# M051DN_v1 register map
File version: 1.0
Registers are 32-bit, read-write, reset 0x0 unless marked. A register's access mark holds for its fields unless they carry their own. Offsets are from the block's base; [hi:lo] are bit positions; {n}, {i} and the like mark numbered series; 'fields as' and 'values as' point back to an identical list.

## GP — GPIO Register Map
Base 0x50004000
{0x0+0x40*i} P{i}_PMD (reset mask 0xFFFF0000) (i=0..4) — P{i} I/O Mode Control
  [15:0] PMDn — Port 0-4 I/O Pin [N] Mode Control. Determine each I/O mode of Px.n pins. Note2: The default value is 0x0000_FFFF and all pins will be quasi-bidirectional mode after chip is powered on (only for M05xxBN). Note3: The initial value of this field is defined by CIOINI (CONFIG[10]) (only for M05xxDN/DE).If CIOINI is set to 1, the default value is 0x0000_FFFF and all pins will be quasi-bidirectional mode after chip powered on.If CIOINI is set to 0, the default value is 0x0000_0000 and all pins will be input tri-state mode after chip powered on.
    0=Px.n is in Input mode; 1=Px.n is in Push-pull Output mode; 2=Px.n is in Open-drain Output mode; 3=Px.n is in Quasi-bidirectional mode
{0x4+0x40*i} P{i}_OFFD (i=0..4) — P{i} Digital Input Path Disable Control
  [23:16] OFFD — Port 0-4 Pin [N] Digital Input Path Disable Control. Each of these bits is used to control if the digital input path of corresponding Px.n pin is disabled. If input is analog signal, users can disable Px.n digital input path to avoid input current leakage.
    0=Px.n digital input path Enabled; 1=Px.n digital input path Disabled (digital input tied to low)
{0x8+0x40*i} P{i}_DOUT reset 0xFF (i=0..4) — P{i} Data Output Value
  [15:0] DOUT — Port 0-4 Pin [N] Output Value. Each of these bits controls the status of a Px.n pin when the Px.n is configured as Push-pull output, Open-drain output or Quasi-bidirectional mode.
    0=Px.n will drive Low if the Px.n pin is configured as Push-pull output, Open-drain output or Quasi-bidirectional mode; 1=Px.n will drive High if the Px.n pin is configured as Push-pull output or Quasi-bidirectional mode
{0xC+0x40*i} P{i}_DMASK (i=0..4) — P{i} Data Output Write Mask
  [7:0] DMASK — Port 0-4 Pin [N] Data Output Write Mask. These bits are used to protect the corresponding Px_DOUT[n] bit. When the DMASK[n] bit is set to 1, the corresponding Px_DOUT[n] bit is protected. If the write signal is masked, writing data to the protect bit is ignored. Note2: This function only protects the corresponding Px_DOUT[n] bit, and will not protect the corresponding Pxn_PDIO bit.
    0=Corresponding Px_DOUT[n] bit can be updated; 1=Corresponding Px_DOUT[n] bit protected
{0x10+0x40*i} P{i}_PIN ro (reset mask 0xFFFFFF00) (i=0..4) — P{i} Pin Value
  [15:0] PIN — Port 0-4 Pin [N] Pin Value. Each bit of the register reflects the actual status of the respective Px.n pin. If the bit is 1, it indicates the corresponding pin status is high; else the pin status is low.
{0x14+0x40*i} P{i}_DBEN (i=0..4) — P{i} De-bounce Enable Control
  [15:0] DBEN — Port 0-4 Pin [N] Input Signal De-bounce Enable Control. DBEN[n] bit is used to enable the de-bounce function for each corresponding bit. If the input signal pulse width cannot be sampled by continuous two de-bounce sample cycle, the input signal transition is seen as the signal bounce and will not trigger the interrupt. The de-bounce clock source is controlled by DBNCECON[4], one de-bounce sample cycle period is controlled by DBNCECON[3:0]. Note2: If Px.n pin is chosen as Power-down wake-up source, user should be disable the de-bounce function before entering Power-down mode to avoid the second interrupt event occurred after system waken up which caused by Px.n de-bounce function.
    0=Px.n de-bounce function Disabled; 1=Px.n de-bounce function Enabled
{0x18+0x40*i} P{i}_IMD (i=0..4) — P{i} Interrupt Mode Control
  [15:0] IMD — Port 0-4 Pin [N] Edge or Level Detection Interrupt Mode Control. IMD[n] bit is used to control the triggered interrupt is by level trigger or by edge trigger. If the interrupt is by edge trigger, the trigger source can be controlled by de-bounce. If the interrupt is by level trigger, the input source is sampled by one HCLK clock and generates the interrupt.
    0=Edge trigger interrupt; 1=Level trigger interrupt
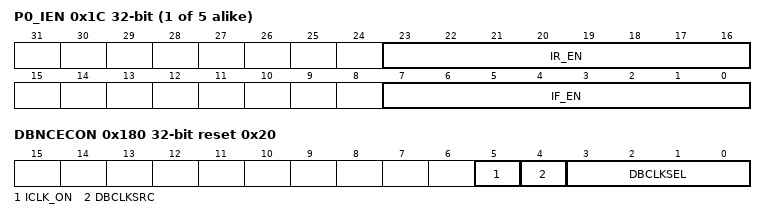
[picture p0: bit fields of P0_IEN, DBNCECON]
{0x1C+0x40*i} P{i}_IEN (i=0..4) — P{i} Interrupt Enable Control
  [23:16] IR_EN — Port 0-4 Pin [N] Interrupt Enable by Input Rising Edge or Input Level High. IR_EN[n] bit is used to enable the interrupt for each of the corresponding input Px.n pin. Set bit to 1 also enable the pin wake-up function. When setting the IR_EN[n] bit to 1 : If the interrupt is level trigger (IMD[n] is 1), the input Px.n pin will generate the interrupt while this pin state is at high level. If the interrupt is edge trigger (IMD[n] is 0), the input Px.n pin will generate the interrupt while this pin state changed from low to high.
    0=Px.n level high or low to high interrupt Disabled; 1=Px.n level high or low to high interrupt Enabled
  [7:0] IF_EN — Port 0-4 Pin [N] Interrupt Enable by Input Falling Edge or Input Level Low. IF_EN[n] bit is used to enable the interrupt for each of the corresponding input Px.n pin. Set bit to 1 also enable the pin wake-up function. When setting the IF_EN[n] bit to 1 : If the interrupt is level trigger (IMD[n] is 1), the input Px.n pin will generate the interrupt while this pin state is at low level. If the interrupt is edge trigger (IMD[n] is 0), the input Px.n pin will generate the interrupt while this pin state changed from high to low.
    0=Px.n level low or high to low interrupt Disabled; 1=Px.n level low or high to low interrupt Enabled
{0x20+0x40*i} P{i}_ISRC (i=0..4) — P{i} Interrupt Source Flag
  [7:0] ISRC — Port 0-4 Pin [N] Interrupt Source Flag. Write :
    0=No action. No interrupt at Px.n; 1=Clear the corresponding pending interrupt. Px.n generates an interrupt
0x180 DBNCECON reset 0x20 — Interrupt De-bounce Control
  [5] ICLK_ON — Interrupt Clock On Mode. Note: It is recommended to turn off this bit to save system power if no special application concern.
    0=Edge detection circuit is active only if I/O pin corresponding Px_IEN bit is set to 1; 1=All I/O pins edge detection circuit is always active after reset
  [4] DBCLKSRC — De-bounce Counter Clock Source Selection
    0=De-bounce counter clock source is the HCLK; 1=De-bounce counter clock source is the 10 kHz internal low speed oscillator
  [3:0] DBCLKSEL — De-bounce Sampling Cycle Selection
    0=Sample interrupt input once per 1 clocks; 1=Sample interrupt input once per 2 clocks; 2=Sample interrupt input once per 4 clocks; 3=Sample interrupt input once per 8 clocks; 4=Sample interrupt input once per 16 clocks; 5=Sample interrupt input once per 32 clocks; 6=Sample interrupt input once per 64 clocks; 7=Sample interrupt input once per 128 clocks; 8=Sample interrupt input once per 256 clocks; 9=Sample interrupt input once per 2*256 clocks; 10=Sample interrupt input once per 4*256 clocks; 11=Sample interrupt input once per 8*256 clocks; 12=Sample interrupt input once per 16*256 clocks; 13=Sample interrupt input once per 32*256 clocks; 14=Sample interrupt input once per 64*256 clocks; 15=Sample interrupt input once per 128*256 clocks
{0x200+4i} P{i:02}_PDIO (reset mask 0xFFFFFFF0) (i=0..7) — GPIO P0.n Pin Data Input/Output
  [0] Pxn_PDIO — GPIO Px.N Pin Data Input/Output. Writing this bit can control one GPIO pin output value. Note2: The writing operation will not be affected by register Px_DMASK[n].
    0=Corresponding GPIO pin set to low; 1=Corresponding GPIO pin set to high
{0x1F8+4i} P{i}_PDIO (reset mask 0xFFFFFFF0) (i=10..17) — GPIO P1.n Pin Data Input/Output
  fields as P00_PDIO
{0x1F0+4i} P{i}_PDIO (reset mask 0xFFFFFFF0) (i=20..27) — GPIO P2.n Pin Data Input/Output
  fields as P00_PDIO
{0x1E8+4i} P{i}_PDIO (reset mask 0xFFFFFFF0) (i=30..37) — GPIO P3.n Pin Data Input/Output
  fields as P00_PDIO
{0x1E0+4i} P{i}_PDIO (reset mask 0xFFFFFFF0) (i=40..47) — GPIO P4.n Pin Data Input/Output
  fields as P00_PDIO
